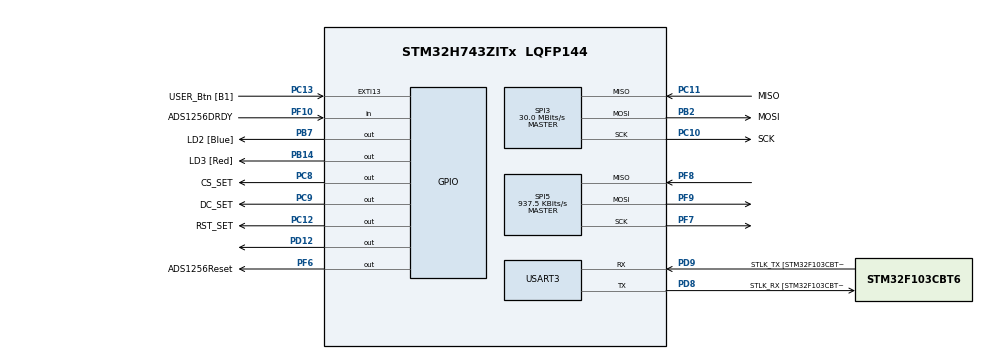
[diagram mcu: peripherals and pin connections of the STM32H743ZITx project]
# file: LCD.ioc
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Mcu.Family=STM32H7
Mcu.Name=STM32H743ZITx
Mcu.Package=LQFP144
NVIC.PriorityGroup=NVIC_PRIORITYGROUP_4
PB14.GPIO_Label=LD3 [Red]
PB14.Signal=GPIO_Output
PB2.GPIO_Label=MOSI
PB2.GPIO_Speed=GPIO_SPEED_FREQ_VERY_HIGH
PB2.Mode=Full_Duplex_Master
PB2.Signal=SPI3_MOSI
PB7.GPIO_Label=LD2 [Blue]
PB7.Signal=GPIO_Output
PC10.GPIO_Label=SCK
PC10.GPIO_Speed=GPIO_SPEED_FREQ_VERY_HIGH
PC10.Mode=Full_Duplex_Master
PC10.Signal=SPI3_SCK
PC11.GPIO_Label=MISO
PC11.GPIO_Speed=GPIO_SPEED_FREQ_VERY_HIGH
PC11.Mode=Full_Duplex_Master
PC11.Signal=SPI3_MISO
PC12.GPIO_Label=RST_SET
PC12.GPIO_Speed=GPIO_SPEED_FREQ_VERY_HIGH
PC12.PinState=GPIO_PIN_RESET
PC12.Signal=GPIO_Output
PC13.GPIO_Label=USER_Btn [B1]
PC13.Signal=GPXTI13
PC14-OSC32_IN\ (OSC32_IN).Mode=LSE-External-Oscillator
PC14-OSC32_IN\ (OSC32_IN).Signal=RCC_OSC32_IN
PC15-OSC32_OUT\ (OSC32_OUT).Mode=LSE-External-Oscillator
PC15-OSC32_OUT\ (OSC32_OUT).Signal=RCC_OSC32_OUT
PC8.GPIO_Label=CS_SET
PC8.GPIO_Speed=GPIO_SPEED_FREQ_VERY_HIGH
PC8.PinState=GPIO_PIN_RESET
PC8.Signal=GPIO_Output
PC9.GPIO_Label=DC_SET
PC9.Signal=GPIO_Output
PD12.Signal=GPIO_Output
PD8.GPIO_Label=STLK_RX [STM32F103CBT6_PA3]
PD8.Mode=Asynchronous
PD8.Signal=USART3_TX
PD9.GPIO_Label=STLK_TX [STM32F103CBT6_PA2]
PD9.Mode=Asynchronous
PD9.Signal=USART3_RX
PF10.GPIO_Label=ADS1256DRDY
PF10.GPIO_PuPd=GPIO_PULLUP
PF10.Signal=GPIO_Input
PF6.GPIO_Label=ADS1256Reset
PF6.GPIO_Speed=GPIO_SPEED_FREQ_VERY_HIGH
PF6.Signal=GPIO_Output
PF7.Mode=Full_Duplex_Master
PF7.Signal=SPI5_SCK
PF8.Mode=Full_Duplex_Master
PF8.Signal=SPI5_MISO
PF9.Mode=Full_Duplex_Master
PF9.Signal=SPI5_MOSI
PH0-OSC_IN\ (PH0).GPIO_Label=MCO
PH0-OSC_IN\ (PH0).Mode=HSE-External-Clock-Source
PH0-OSC_IN\ (PH0).Signal=RCC_OSC_IN
PH1-OSC_OUT\ (PH1).Mode=HSE-External-Clock-Source
PH1-OSC_OUT\ (PH1).Signal=RCC_OSC_OUT
ProjectManager.HeapSize=0x200
ProjectManager.StackSize=0x400
ProjectManager.TargetToolchain=MDK-ARM V5
RCC.48MHZClocksFreq_Value=24000000
RCC.ADCFreq_Value=16125000
RCC.AHBFreq_Value=216000000
RCC.APB1CLKDivider=RCC_HCLK_DIV4
RCC.APB1Freq_Value=120000000
RCC.APB1TimFreq_Value=108000000
RCC.APB2CLKDivider=RCC_HCLK_DIV2
RCC.APB2Freq_Value=120000000
RCC.APB2TimFreq_Value=216000000
RCC.APB3Freq_Value=120000000
RCC.APB4Freq_Value=120000000
RCC.CortexFreq_Value=480000000
RCC.D1PPRE=RCC_APB3_DIV2
RCC.D2PPRE1=RCC_APB1_DIV2
RCC.D2PPRE2=RCC_APB2_DIV2
RCC.D3PPRE=RCC_APB4_DIV2
RCC.DIVM1=1
RCC.DIVN1=120
RCC.DIVQ1=4
RCC.HCLKFreq_Value=240000000
RCC.HPRE=RCC_HCLK_DIV2
RCC.HSE_VALUE=8000000
RCC.HSI_VALUE=64000000
RCC.PLLFRACN=0
RCC.PLLM=25
RCC.PLLMUL=RCC_PLL_MUL9
RCC.PLLN=432
RCC.PLLQ=9
RCC.PLLSourceVirtual=RCC_PLLSOURCE_HSE
RCC.PRESCALERUSB=RCC_USBCLKSOURCE_PLL_DIV1_5
RCC.PWR_Regulator_Voltage_Scale=PWR_REGULATOR_VOLTAGE_SCALE0
RCC.SYSCLKFreq_VALUE=480000000
RCC.SYSCLKSource=RCC_SYSCLKSOURCE_PLLCLK
RCC.SYSCLKSourceVirtual=RCC_SYSCLKSOURCE_PLLCLK
RCC.USBFreq_Value=240000000
RCC.VCOOutputFreq_Value=432000000
SPI3.BaudRatePrescaler=SPI_BAUDRATEPRESCALER_8
SPI3.CLKPhase=SPI_PHASE_2EDGE
SPI3.CLKPolarity=SPI_POLARITY_HIGH
SPI3.CalculateBaudRate=30.0 MBits/s
SPI3.DataSize=SPI_DATASIZE_8BIT
SPI3.Direction=SPI_DIRECTION_2LINES
SPI3.Mode=SPI_MODE_MASTER
SPI3.NSSPMode=SPI_NSS_PULSE_DISABLE
SPI3.VirtualType=VM_MASTER
SPI5.BaudRatePrescaler=SPI_BAUDRATEPRESCALER_128
SPI5.CLKPhase=SPI_PHASE_2EDGE
SPI5.CalculateBaudRate=937.5 KBits/s
SPI5.DataSize=SPI_DATASIZE_8BIT
SPI5.Direction=SPI_DIRECTION_2LINES
SPI5.Mode=SPI_MODE_MASTER
SPI5.VirtualType=VM_MASTER
USART3.VirtualMode-Asynchronous=VM_ASYNC
board=NUCLEO-H743ZI

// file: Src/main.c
/* USER CODE BEGIN Header */
/**
  ******************************************************************************
  * @file           : main.c
  * @brief          : Main program body
  ******************************************************************************
  * @attention
  *
  * <h2><center>&copy; Copyright (c) 2019 STMicroelectronics.
  * All rights reserved.</center></h2>
  *
  * This software component is licensed by ST under BSD 3-Clause license,
  * the "License"; You may not use this file except in compliance with the
  * License. You may obtain a copy of the License at:
  *                        opensource.org/licenses/BSD-3-Clause
  *
  ******************************************************************************
  */
/* USER CODE END Header */

#include "main.h"
#include "spi.h"
#include "usart.h"
#include "gpio.h"

/* USER CODE BEGIN Includes */
#include "gui.h"
/* USER CODE END Includes */

void SystemClock_Config(void);

int main(void)
{

  /* MCU Configuration--------------------------------------------------------*/

  /* Reset of all peripherals, Initializes the Flash interface and the Systick. */
  HAL_Init();

  /* Configure the system clock */
  SystemClock_Config();

  /* Initialize all configured peripherals */
  MX_GPIO_Init();
  MX_USART3_UART_Init();
  MX_SPI3_Init();
  MX_SPI5_Init();
  /* USER CODE BEGIN 2 */
	Lcd_Init();
	Lcd_Clear(RED);
  /* USER CODE END 2 */

  /* Infinite loop */
  /* USER CODE BEGIN WHILE */
  while (1)
  {

		Gui_DrawLine(0,0,100,100,WHITE);
    /* USER CODE END WHILE */

  }
}

void SystemClock_Config(void)
{
  RCC_OscInitTypeDef RCC_OscInitStruct = {0};
  RCC_ClkInitTypeDef RCC_ClkInitStruct = {0};
  RCC_PeriphCLKInitTypeDef PeriphClkInitStruct = {0};

  /** Supply configuration update enable
  */
  HAL_PWREx_ConfigSupply(PWR_LDO_SUPPLY);
  /** Configure the main internal regulator output voltage
  */
  __HAL_PWR_VOLTAGESCALING_CONFIG(PWR_REGULATOR_VOLTAGE_SCALE0);

  while(!__HAL_PWR_GET_FLAG(PWR_FLAG_VOSRDY)) {}
  /** Initializes the CPU, AHB and APB busses clocks
  */
  RCC_OscInitStruct.OscillatorType = RCC_OSCILLATORTYPE_HSE;
  RCC_OscInitStruct.HSEState = RCC_HSE_BYPASS;
  RCC_OscInitStruct.PLL.PLLState = RCC_PLL_ON;
  RCC_OscInitStruct.PLL.PLLSource = RCC_PLLSOURCE_HSE;
  RCC_OscInitStruct.PLL.PLLM = 1;
  RCC_OscInitStruct.PLL.PLLN = 120;
  RCC_OscInitStruct.PLL.PLLP = 2;
  RCC_OscInitStruct.PLL.PLLQ = 4;
  RCC_OscInitStruct.PLL.PLLR = 2;
  RCC_OscInitStruct.PLL.PLLRGE = RCC_PLL1VCIRANGE_3;
  RCC_OscInitStruct.PLL.PLLVCOSEL = RCC_PLL1VCOWIDE;
  RCC_OscInitStruct.PLL.PLLFRACN = 0;
  if (HAL_RCC_OscConfig(&RCC_OscInitStruct) != HAL_OK)
  {
    Error_Handler();
  }
  /** Initializes the CPU, AHB and APB busses clocks
  */
  RCC_ClkInitStruct.ClockType = RCC_CLOCKTYPE_HCLK|RCC_CLOCKTYPE_SYSCLK
                              |RCC_CLOCKTYPE_PCLK1|RCC_CLOCKTYPE_PCLK2
                              |RCC_CLOCKTYPE_D3PCLK1|RCC_CLOCKTYPE_D1PCLK1;
  RCC_ClkInitStruct.SYSCLKSource = RCC_SYSCLKSOURCE_PLLCLK;
  RCC_ClkInitStruct.SYSCLKDivider = RCC_SYSCLK_DIV1;
  RCC_ClkInitStruct.AHBCLKDivider = RCC_HCLK_DIV2;
  RCC_ClkInitStruct.APB3CLKDivider = RCC_APB3_DIV2;
  RCC_ClkInitStruct.APB1CLKDivider = RCC_APB1_DIV2;
  RCC_ClkInitStruct.APB2CLKDivider = RCC_APB2_DIV2;
  RCC_ClkInitStruct.APB4CLKDivider = RCC_APB4_DIV2;

  if (HAL_RCC_ClockConfig(&RCC_ClkInitStruct, FLASH_LATENCY_4) != HAL_OK)
  {
    Error_Handler();
  }
  PeriphClkInitStruct.PeriphClockSelection = RCC_PERIPHCLK_USART3|RCC_PERIPHCLK_SPI5
                              |RCC_PERIPHCLK_SPI3;
  PeriphClkInitStruct.Spi123ClockSelection = RCC_SPI123CLKSOURCE_PLL;
  PeriphClkInitStruct.Spi45ClockSelection = RCC_SPI45CLKSOURCE_D2PCLK1;
  PeriphClkInitStruct.Usart234578ClockSelection = RCC_USART234578CLKSOURCE_D2PCLK1;
  if (HAL_RCCEx_PeriphCLKConfig(&PeriphClkInitStruct) != HAL_OK)
  {
    Error_Handler();
  }
}

void Error_Handler(void)
{
}

/************************ (C) COPYRIGHT STMicroelectronics *****END OF FILE****/
